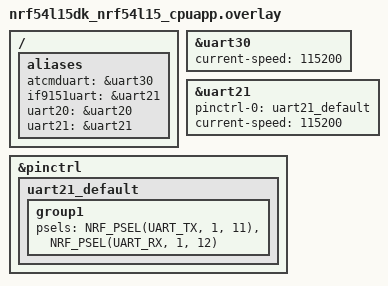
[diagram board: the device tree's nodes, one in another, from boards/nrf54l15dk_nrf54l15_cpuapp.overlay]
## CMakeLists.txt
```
cmake_minimum_required(VERSION 3.20.0)
find_package(Zephyr REQUIRED HINTS $ENV{ZEPHYR_BASE})
project(nus_at_cmd)

# 納入 src 和 drivers 目錄
add_subdirectory(drivers)

target_sources(app PRIVATE
        src/main.c
        src/at_command.c
        src/hmi_uart.c
        src/cat.c
        src/value_reporter.c
        src/sensor_handler.c
)
target_link_libraries(app PRIVATE drivers__sensor__atmel__m90e26)
```

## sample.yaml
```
sample:
  name: Bluetooth Peripheral NUS
  description: Demonstrates the NUS GATT Service (Nordic UART Service)
tests:
  sample.bluetooth.peripheral_nus:
    harness: bluetooth
    platform_allow:
      - qemu_cortex_m3
      - qemu_x86
      - nrf52840dk/nrf52840
      - nrf54l15dk/nrf54l15
    integration_platforms:
      - qemu_cortex_m3
    tags: bluetooth
```

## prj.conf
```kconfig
CONFIG_BT=y
CONFIG_BT_PERIPHERAL=y
CONFIG_BT_ZEPHYR_NUS=y

CONFIG_UART_CONSOLE=y
CONFIG_NEWLIB_LIBC=y
CONFIG_NEWLIB_LIBC_FLOAT_PRINTF=y
CONFIG_RING_BUFFER=y
CONFIG_LOG=y

# 啟用 UART 驅動
CONFIG_UART_ASYNC_API=y
# CONFIG_UART_INTERRUPT_DRIVEN=y
CONFIG_UART_USE_RUNTIME_CONFIGURE=y
# 啟用日誌
CONFIG_LOG=y
CONFIG_LOG_DEFAULT_LEVEL=3
CONFIG_LOG_MODE_DEFERRED=y

CONFIG_MAIN_STACK_SIZE=2048

CONFIG_RTIO=y
#CONFIG_M90E26_UART_DRIVER=y
```

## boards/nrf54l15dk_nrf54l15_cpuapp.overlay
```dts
/ {
    aliases {
        atcmduart = &uart30;
        if9151uart= &uart21;
        uart20 = &uart20;
        uart21 = &uart21;
    };
};

&uart30 {
    status = "okay";
    current-speed = <115200>;
};

&uart21 {
    status = "okay";
    pinctrl-0 = <&uart21_default>;
    pinctrl-names = "default";
    current-speed = <115200>;
};

&pinctrl {
    uart21_default: uart21_default {
        group1 {
            psels = <NRF_PSEL(UART_TX, 1, 11)>, <NRF_PSEL(UART_RX, 1, 12)>;
        };
    };
};
```

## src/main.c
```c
/*
 * Copyright (c) 2024 Croxel, Inc.
 *
 * SPDX-License-Identifier: Apache-2.0
 */

#include <zephyr/kernel.h>
#include <zephyr/bluetooth/bluetooth.h>
#include <zephyr/bluetooth/services/nus.h>
#include <zephyr/sys/ring_buffer.h>
#include "value_reporter.h"
#include "sensor_handler.h"

#define DEVICE_NAME		CONFIG_BT_DEVICE_NAME
#define DEVICE_NAME_LEN		(sizeof(DEVICE_NAME) - 1)

extern struct ring_buf uart_at_ringbuf;
static const struct bt_data ad[] = {
	BT_DATA_BYTES(BT_DATA_FLAGS, (BT_LE_AD_GENERAL | BT_LE_AD_NO_BREDR)),
	BT_DATA(BT_DATA_NAME_COMPLETE, DEVICE_NAME, DEVICE_NAME_LEN),
};

static const struct bt_data sd[] = {
	BT_DATA_BYTES(BT_DATA_UUID128_ALL, BT_UUID_NUS_SRV_VAL),
};

static void notif_enabled(bool enabled, void *ctx)
{
	ARG_UNUSED(ctx);

	printk("%s() - %s\n", __func__, (enabled ? "Enabled" : "Disabled"));
}

static void received(struct bt_conn *conn, const void *data, uint16_t len, void *ctx)
{
	char message[CONFIG_BT_L2CAP_TX_MTU + 1] = "";

	ARG_UNUSED(conn);
	ARG_UNUSED(ctx);

	memcpy(message, data, MIN(sizeof(message) - 1, len));
	if (ring_buf_put(&uart_at_ringbuf
                , data
                , len) == 0) {
                printk("BT: Failed to put message in RX queue (full?).");
            }
	printk("%s() - Len: %d, Message: %s\n", __func__, len, message);
}

struct bt_nus_cb nus_listener = {
	.notif_enabled = notif_enabled,
	.received = received,
};

int main(void)
{
	int err;

	printk("Sample - Bluetooth Peripheral NUS\n");

	err = bt_nus_cb_register(&nus_listener, NULL);
	if (err) {
		printk("Failed to register NUS callback: %d\n", err);
		return err;
	}

	err = bt_enable(NULL);
	if (err) {
		printk("Failed to enable bluetooth: %d\n", err);
		return err;
	}

	err = bt_le_adv_start(BT_LE_ADV_CONN_FAST_1, ad, ARRAY_SIZE(ad), sd, ARRAY_SIZE(sd));
	if (err) {
		printk("Failed to start advertising: %d\n", err);
		return err;
	}
	sensor_handler_init();
	value_reporter_start();
	printk("Initialization complete\n");

	while (true) {
		k_sleep(K_SECONDS(1));
	}

	return 0;
}
```

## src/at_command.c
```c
#include <zephyr/kernel.h>
#include <zephyr/drivers/uart.h>
#include <zephyr/logging/log.h>
#include <string.h>
#include <stdio.h>
#include <zephyr/sys/ring_buffer.h>
#include "hmi_uart.h"
#include "cat.h"
#include "value_reporter.h"

LOG_MODULE_REGISTER(at_parser_app, LOG_LEVEL_INF);

// --- Zephyr 相關定義 ---
#define STACK_SIZE 8192
#define THREAD_PRIORITY 7
#define AT_CMD_UART DT_ALIAS(atcmduart)
RING_BUF_DECLARE(uart_at_ringbuf, 1024);
struct hmi_uart_data at_cmd_uart_instance_data = {.dev = DEVICE_DT_GET(AT_CMD_UART), .rx_rbuf = &uart_at_ringbuf};
K_MUTEX_DEFINE(cat_mutex);

// --- 全局變數定義 ---
static char g_manufacture_id[32] = "MyCompany";
static char g_model_id[32] = "AT_Parser_Demo";
static char g_revision[32] = "v1.0.0";
static char g_serial_number[32] = "1234567890";
static char g_hardware_revision[32] = "HW_A1";
static uint8_t g_sysreg_rw = 0;
static uint32_t g_sysreg_reg = 0;
static uint32_t g_sysreg_sensor_id = 0;
static uint32_t g_sysreg_value = 0;
static uint32_t g_sysreg_interval = 0;
static char g_mqtt_client_id[64] = "cat_parser_client";
static uint16_t g_mqtt_keep_alive = 60;
static uint8_t g_mqtt_clean_session = 0;

static char g_working_buffer[256];
static bool g_quit_flag = false;

// --- 命令處理函式宣告 ---
static cat_return_state cmd_help_run(const struct cat_command *cmd);
static cat_return_state cmd_cgmi_run(const struct cat_command *cmd);
static cat_return_state cmd_cgmi_test(const struct cat_command *cmd, uint8_t *data, size_t *data_size, const size_t max_data_size);
static cat_return_state cmd_cgmm_run(const struct cat_command *cmd);
static cat_return_state cmd_cgmm_test(const struct cat_command *cmd, uint8_t *data, size_t *data_size, const size_t max_data_size);
static cat_return_state cmd_cgmr_run(const struct cat_command *cmd);
static cat_return_state cmd_cgmr_test(const struct cat_command *cmd, uint8_t *data, size_t *data_size, const size_t max_data_size);
static cat_return_state cmd_cgsn_run(const struct cat_command *cmd);
static cat_return_state cmd_cgsn_test(const struct cat_command *cmd, uint8_t *data, size_t *data_size, const size_t max_data_size);
static cat_return_state cmd_cgmh_run(const struct cat_command *cmd);
static cat_return_state cmd_cgmh_test(const struct cat_command *cmd, uint8_t *data, size_t *data_size, const size_t max_data_size);
static cat_return_state cmd_sysreg_write(const struct cat_command *cmd, const uint8_t *data, const size_t data_size, const size_t args_num);
static cat_return_state cmd_sysreg_test(const struct cat_command *cmd, uint8_t *data, size_t *data_size, const size_t max_data_size);
static cat_return_state cmd_xmqttcfg_read(const struct cat_command *cmd, uint8_t *data, size_t *data_size, const size_t max_data_size);
static cat_return_state cmd_xmqttcfg_write(const struct cat_command *cmd, const uint8_t *data, const size_t data_size, const size_t args_num);
static cat_return_state cmd_xmqttcfg_test(const struct cat_command *cmd, uint8_t *data, size_t *data_size, const size_t max_data_size);

// --- 命令變數描述符定義 ---
static struct cat_variable g_sysreg_vars[] = {
    { .name = "r/w", .type = CAT_VAR_UINT_DEC, .data = &g_sysreg_rw, .data_size = sizeof(g_sysreg_rw), .access = CAT_VAR_ACCESS_READ_WRITE },
    { .name = "sensor_id", .type = CAT_VAR_UINT_DEC, .data = &g_sysreg_sensor_id, .data_size = sizeof(g_sysreg_sensor_id), .access = CAT_VAR_ACCESS_READ_WRITE },
    { .name = "reg", .type = CAT_VAR_BUF_HEX, .data = &g_sysreg_reg, .data_size = sizeof(g_sysreg_reg), .access = CAT_VAR_ACCESS_READ_WRITE },
    { .name = "value", .type = CAT_VAR_UINT_DEC, .data = &g_sysreg_value, .data_size = sizeof(g_sysreg_value), .access = CAT_VAR_ACCESS_READ_WRITE },
    { .name = "interval", .type = CAT_VAR_UINT_DEC, .data = &g_sysreg_interval, .data_size = sizeof(g_sysreg_interval), .access = CAT_VAR_ACCESS_READ_WRITE },
};

static struct cat_variable g_mqtt_vars[] = {
    { .name = "client_id", .type = CAT_VAR_BUF_STRING, .data = &g_mqtt_client_id, .data_size = sizeof(g_mqtt_client_id), .access = CAT_VAR_ACCESS_READ_WRITE },
    { .name = "keep_alive", .type = CAT_VAR_UINT_DEC, .data = &g_mqtt_keep_alive, .data_size = sizeof(g_mqtt_keep_alive), .access = CAT_VAR_ACCESS_READ_WRITE },
    { .name = "clean_session", .type = CAT_VAR_UINT_DEC, .data = &g_mqtt_clean_session, .data_size = sizeof(g_mqtt_clean_session), .access = CAT_VAR_ACCESS_READ_WRITE },
};

// --- 命令描述符定義 ---
static struct cat_command g_cmds[] = {
    { .name = "+CGMI", .description = "Requests manufacture identification.", .run = cmd_cgmi_run, .test = cmd_cgmi_test },
    { .name = "+CGMM", .description = "Requests model identification.", .run = cmd_cgmm_run, .test = cmd_cgmm_test },
    { .name = "+CGMR", .description = "Requests revision identification.", .run = cmd_cgmr_run, .test = cmd_cgmr_test },
    { .name = "+CGSN", .description = "Requests product serial number identification.", .run = cmd_cgsn_run, .test = cmd_cgsn_test },
    { .name = "+CGMH", .description = "Requests hardware revision.", .run = cmd_cgmh_run, .test = cmd_cgmh_test },
    {
        .name = "+SYSREG",
        .description = "System register R/W operation.",
        .write = cmd_sysreg_write,
        .test = cmd_sysreg_test,
        .var = g_sysreg_vars,
        .var_num = sizeof(g_sysreg_vars) / sizeof(g_sysreg_vars[0]),
    },
    {
        .name = "#XMQTTCFG",
        .description = "MQTT client configuration.",
        .write = cmd_xmqttcfg_write,
        .read = cmd_xmqttcfg_read,
        .test = cmd_xmqttcfg_test,
        .var = g_mqtt_vars,
        .var_num = sizeof(g_mqtt_vars) / sizeof(g_mqtt_vars[0]),
    },
    { .name = "#HELP", .description = "Prints a list of all available commands.", .run = cmd_help_run },
};

// --- Zephyr I/O 介面實現 ---
static int write_char(char ch) {
    LOG_DBG("Sent: %c\n",(ch));
    hmi_uart_send(at_cmd_uart_instance_data.dev, &ch, 1);
    return 1;
}

static int read_char(char *ch) {
    int ret = 0;
    ret = ring_buf_get(&uart_at_ringbuf, ch, 1);
    if(ret != 0)
    {
        LOG_DBG("Get: %c\n",(uint8_t)(*ch));
        //LOG_INF("head:%d,tail:%d,base:%d\n",uart_at_ringbuf.get_head,uart_at_ringbuf.get_tail,uart_at_ringbuf.get_base);
        
        return 1;
    }
    return 0;
}

// --- 互斥鎖介面實現 ---
static int mutex_lock(void) {
    return k_mutex_lock(&cat_mutex, K_FOREVER);
}

static int mutex_unlock(void) {
    return k_mutex_unlock(&cat_mutex);
}

static struct cat_io_interface g_iface = {
    .read = read_char,
    .write = write_char
};

static struct cat_mutex_interface g_mutex = {
    .lock = mutex_lock,
    .unlock = mutex_unlock
};

static cat_return_state cmd_help_run(const struct cat_command *cmd) {
    LOG_INF("Execute Help");
    return CAT_RETURN_STATE_PRINT_CMD_LIST_OK;
}

static cat_return_state cmd_cgmi_run(const struct cat_command *cmd) {
    printk("%s\n", g_manufacture_id);
    return CAT_RETURN_STATE_OK;
}
static cat_return_state cmd_cgmi_test(const struct cat_command *cmd, uint8_t *data, size_t *data_size, const size_t max_data_size) {
    return CAT_RETURN_STATE_OK;
}

static cat_return_state cmd_cgmm_run(const struct cat_command *cmd) {
    printk("%s\n", g_model_id);
    return CAT_RETURN_STATE_OK;
}
static cat_return_state cmd_cgmm_test(const struct cat_command *cmd, uint8_t *data, size_t *data_size, const size_t max_data_size) {
    return CAT_RETURN_STATE_OK;
}

static cat_return_state cmd_cgmr_run(const struct cat_command *cmd) {
    printk("%s\n", g_revision);
    return CAT_RETURN_STATE_OK;
}
static cat_return_state cmd_cgmr_test(const struct cat_command *cmd, uint8_t *data, size_t *data_size, const size_t max_data_size) {
    return CAT_RETURN_STATE_OK;
}

static cat_return_state cmd_cgsn_run(const struct cat_command *cmd) {
    printk("%s\n", g_serial_number);
    return CAT_RETURN_STATE_OK;
}
static cat_return_state cmd_cgsn_test(const struct cat_command *cmd, uint8_t *data, size_t *data_size, const size_t max_data_size) {
    return CAT_RETURN_STATE_OK;
}

static cat_return_state cmd_cgmh_run(const struct cat_command *cmd) {
    printk("%s\n", g_hardware_revision);
    return CAT_RETURN_STATE_OK;
}
static cat_return_state cmd_cgmh_test(const struct cat_command *cmd, uint8_t *data, size_t *data_size, const size_t max_data_size) {
    return CAT_RETURN_STATE_OK;
}

static cat_return_state cmd_sysreg_write(const struct cat_command *cmd, const uint8_t *data, const size_t data_size, const size_t args_num) {
    uint32_t result = 0;

    LOG_INF("+SYSREG:%d, %u, %02X,%u,%u\n", g_sysreg_rw, g_sysreg_sensor_id, g_sysreg_reg, g_sysreg_value, g_sysreg_interval);
    result = value_reporter_set_report_period(g_sysreg_sensor_id, g_sysreg_reg, g_sysreg_interval);
    if(result != g_sysreg_interval)
    {
        return CAT_RETURN_STATE_ERROR;
    }

    return CAT_RETURN_STATE_OK;
}
static cat_return_state cmd_sysreg_test(const struct cat_command *cmd, uint8_t *data, size_t *data_size, const size_t max_data_size) {
    return CAT_RETURN_STATE_OK;
}

static cat_return_state cmd_xmqttcfg_read(const struct cat_command *cmd, uint8_t *data, size_t *data_size, const size_t max_data_size) {
    int written = snprintf((char*)data, max_data_size, "+XMQTTCFG:\"%s\",%u,%u", g_mqtt_client_id, g_mqtt_keep_alive, g_mqtt_clean_session);
    if (written > 0) {
        *data_size = written;
    }
    return CAT_RETURN_STATE_DATA_OK;
}
static cat_return_state cmd_xmqttcfg_write(const struct cat_command *cmd, const uint8_t *data, const size_t data_size, const size_t args_num) {
    LOG_INF("MQTT config updated: client_id=\"%s\", keep_alive=%u, clean_session=%u", g_mqtt_client_id, g_mqtt_keep_alive, g_mqtt_clean_session);
    return CAT_RETURN_STATE_OK;
}
static cat_return_state cmd_xmqttcfg_test(const struct cat_command *cmd, uint8_t *data, size_t *data_size, const size_t max_data_size) {
    return CAT_RETURN_STATE_OK;
}

// --- AT 解析器執行緒 ---
static void at_parser_thread(void *p1, void *p2, void *p3) {
    struct cat_object at;
    
    struct cat_command_group g_cmd_group_obj = {
        .cmd = g_cmds,
        .cmd_num = sizeof(g_cmds) / sizeof(g_cmds[0]),
    };
    
    struct cat_command_group *g_cmd_desc[] = {
        &g_cmd_group_obj
    };

    struct cat_descriptor g_desc = {
        .cmd_group = g_cmd_desc,
        .cmd_group_num = sizeof(g_cmd_desc) / sizeof(g_cmd_desc[0]),
        .buf = (uint8_t *)g_working_buffer,
        .buf_size = sizeof(g_working_buffer),
    };

    if (hmi_uart_init_instance(&at_cmd_uart_instance_data, 115200)) {
        LOG_ERR("AT CMD UART device not ready!");
        return;
    }
    
    cat_init(&at, &g_desc, &g_iface, &g_mutex);
    LOG_INF("AT Command Parser Thread Started");
    
    // Initial banner
    LOG_INF("AT Command Parser Demo\n");
    LOG_INF("Type AT#HELP to see the command list.\n");

    while (!g_quit_flag) {
        cat_service(&at);
        k_msleep(1);
    }
}

K_THREAD_DEFINE(at_parser_tid, STACK_SIZE, at_parser_thread, NULL, NULL, NULL, THREAD_PRIORITY, 0, 0);
```

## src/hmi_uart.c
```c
#include "hmi_uart.h"
#include <string.h>
#include <zephyr/sys/ring_buffer.h>

// 註冊日誌模組
LOG_MODULE_REGISTER(hmi_uart_module, LOG_LEVEL_INF);

// 靜態函數聲明
static void hmi_uart_callback_internal(const struct device *dev, struct uart_event *evt, void *user_data);

// 內部 UART 回調函數
// 這個回調函數將處理所有由 Zephyr UART 驅動發出的事件，並將其分發到正確的 hmi_uart_data 實例。
static void hmi_uart_callback_internal(const struct device *dev, struct uart_event *evt, void *user_data)
{
    struct hmi_uart_data *data = (struct hmi_uart_data *)user_data;

    if (data == NULL) {
        LOG_ERR("UART callback received NULL user_data for %s!", dev->name);
        return;
    }

    switch (evt->type) {
        case UART_RX_RDY: {
            LOG_HEXDUMP_DBG(&evt->data.rx.buf[evt->data.rx.offset], evt->data.rx.len, "Put:");
            if (ring_buf_put(data->rx_rbuf
                , &evt->data.rx.buf[evt->data.rx.offset]
                , evt->data.rx.len) == 0) {
                LOG_WRN("%s: 1 Failed to put message in RX queue (full?).", data->dev->name);
            }
            break;
        }
        case UART_RX_STOPPED: {
            //LOG_INF("%s: UART_RX_STOPPED", dev->name);
            break;
        }
        case UART_RX_BUF_REQUEST:
        {
            if(data->rx_buf_idx == 0)
            {
                data->rx_buf_idx = 1;
            }else
            {
                data->rx_buf_idx = 0;
            }
            uart_rx_buf_rsp(dev, data->rx_buf[data->rx_buf_idx], HMI_UART_RX_MSG_SIZE);
            break;
        }
        case UART_RX_BUF_RELEASED:
            // 緩衝區釋放事件，用於資源管理
            break;
        case UART_RX_DISABLED:
        {
            int ret = 0;
            if(data->rx_buf_idx == 0)
            {
                data->rx_buf_idx = 1;
            }else
            {
                data->rx_buf_idx = 0;
            }
            ret = uart_rx_enable(dev, data->rx_buf[data->rx_buf_idx], HMI_UART_RX_MSG_SIZE, 100);
            if (ret) {
                LOG_ERR("啟用 UART %s 接收失敗: %d", dev->name, ret);
            }
            //LOG_INF("%s: UART_RX_DISABLED", dev->name);
            break;
        }
        case UART_TX_DONE:
            // 傳輸完成事件。如果需要，可以在此處理 TX 完成的邏輯
            // 例如，釋放 TX 緩衝區或通知等待的線程
            LOG_DBG("%s: UART_TX_DONE", dev->name);
            break;

        case UART_TX_ABORTED:
            //LOG_WRN("%s: UART_EVT_TX_ABORTED", dev->name);
            break;

        default:
            // 處理其他未知的 UART 事件
            break;
    }
}

int hmi_uart_init_instance(struct hmi_uart_data *instance_data, uint32_t baud_rate)
{
    const struct device *uart_dev = instance_data->dev;
    struct uart_config uart_cfg = {
        .baudrate = baud_rate,
        .parity = UART_CFG_PARITY_NONE,
        .stop_bits = UART_CFG_STOP_BITS_1,
        .data_bits = UART_CFG_DATA_BITS_8,
        .flow_ctrl = UART_CFG_FLOW_CTRL_NONE
    };
    int ret;

    if (!device_is_ready(uart_dev)) {
        LOG_ERR("UART 設備 %s 未準備就緒！", uart_dev->name);
        return -ENODEV;
    }

    if (instance_data == NULL) {
        LOG_ERR("hmi_uart_init_instance 接收到 NULL 指針！");
        return -EINVAL;
    }

    // 將外部提供的數據結構和消息佇列指針賦值給實例
    instance_data->dev = uart_dev;
    instance_data->rx_buf_pos = 0;

    ret = uart_configure(uart_dev, &uart_cfg);
    if (ret) {
        LOG_ERR("配置 UART 設備 %s 失敗: %d", uart_dev->name, ret);
        return ret;
    }

    // 設置回調函數，將實例數據指針作為 user_data 傳遞
    ret = uart_callback_set(uart_dev, hmi_uart_callback_internal, (void *)instance_data);
    if (ret) {
        LOG_ERR("設定 UART %s 回調失敗: %d", uart_dev->name, ret);
        return ret;
    }

    // 啟用接收，使用實例的接收緩衝區
    ret = uart_rx_enable(uart_dev, instance_data->rx_buf[0], HMI_UART_RX_MSG_SIZE, 100);
    if (ret) {
        LOG_ERR("啟用 UART %s 接收失敗: %d", uart_dev->name, ret);
        return ret;
    }

    LOG_INF("HMI UART 模組 %s 初始化成功，波特率: %d", uart_dev->name, baud_rate);
    return 0;
}

int hmi_uart_send(const struct device *uart_dev, const uint8_t *data, size_t len)
{
    if (!device_is_ready(uart_dev)) {
        LOG_ERR("UART 設備 %s 未準備就緒，無法傳送！", uart_dev->name);
        return -ENODEV;
    }

    int ret = uart_tx(uart_dev, data, len, SYS_FOREVER_US);
    if (ret < 0) {
        LOG_ERR("UART %s 寫入 FIFO 失敗: %d", uart_dev->name, ret);
    }
    return ret; // 返回
}
```

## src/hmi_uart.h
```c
#ifndef HMI_UART_H__
#define HMI_UART_H__

#include <zephyr/kernel.h>
#include <zephyr/drivers/uart.h>
#include <zephyr/logging/log.h>

// UART 接收緩衝區大小
#define HMI_UART_RX_MSG_SIZE (64) //
#define HMI_UART_RX_BUFF_NEM (2)
/**
 * @brief HMI UART 實例的數據結構。
 * 包含每個 UART 實例的運行時數據。
 */
struct hmi_uart_data {
    const struct device *dev;         // UART 設備指針
    uint8_t rx_buf[HMI_UART_RX_BUFF_NEM][HMI_UART_RX_MSG_SIZE]; // 接收緩衝區
    uint8_t rx_buf_idx;
    size_t rx_buf_pos;                // 接收緩衝區當前位置
    struct ring_buf *rx_rbuf;           // 綁定到此實例的接收消息隊列指針
};

/**
 * @brief 初始化 HMI UART 模組的特定實例。
 *
 * @param instance_data 指向 HMI UART 數據結構的指針，用於儲存實例的運行時數據。
 * @param baud_rate 要設置的 UART 波特率。
 * 此數據結構和其內部消息佇列應由外部調用者定義和管理。
 *
 * @return 回傳傳送成功或失敗，0為成功，負數 errno 表示失敗。
 */
int hmi_uart_init_instance(struct hmi_uart_data *instance_data, uint32_t baud_rate);

/**
 * @brief 向指定的 HMI UART 設備發送數據 (非阻塞)。
 *
 * @param uart_dev 指向要發送數據的 UART 設備的指針。
 * @param data 指向要發送數據的緩衝區的指針。
 * @param len 要發送的數據長度。
 *
 * @return 回傳傳送成功或失敗，0為成功，負數 errno 表示失敗。
 */
int hmi_uart_send(const struct device *uart_dev, const uint8_t *data, size_t len);

#endif // HMI_UART_H__
```

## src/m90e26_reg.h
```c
#ifndef M90E26_REG_H_
#define M90E26_REG_H_

#define TOTAL_REG_NUM   21
enum ATM90E26_ENG_REGSTERS {
    APENG = 0x40,
    ANENG = 0x41,
    ATENG = 0x42,
    RPENG = 0x43,
    RNENG = 0x44,
    RTENG = 0x45,
    ENSTAT = 0x46,
    IRMS = 0x48,
    URMS = 0x49,
    PMEAN = 0x4A,
    QMEAN = 0x4B,
    FREQ = 0x4C,
    POWERF = 0x4D,
    PANG = 0x4E,
    SMEAN = 0x4F,
    IRMS2 = 0x68,
    PMEAN2 = 0x6A,
    QMEAN2 = 0x6B,
    POWERF2 = 0x6D,
    PANG2 = 0x6E,
    SMEAN2 = 0x6F
};

#endif /* M90E26_REG_H_ */
```

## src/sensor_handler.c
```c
#include <zephyr/kernel.h>
#include <zephyr/device.h>
#include <zephyr/rtio/rtio.h>
#include <zephyr/sys/byteorder.h>
#include <zephyr/sys/atomic.h>
#include <zephyr/init.h>
#include <zephyr/logging/log.h>

#include "sensor_handler.h"
#include "m90e26_reg.h"

LOG_MODULE_REGISTER(sensor_handler, LOG_LEVEL_INF);

// --- 內部定義 ---
static const uint8_t regs_to_poll[] = {
	APENG, ANENG, ATENG, RPENG, RNENG, RTENG, ENSTAT,
	IRMS, URMS, PMEAN, QMEAN, FREQ, POWERF, PANG, SMEAN,
	IRMS2, PMEAN2, QMEAN2, POWERF2, PANG2, SMEAN2
};

#define NUM_REGS_TO_POLL (sizeof(regs_to_poll) / sizeof(regs_to_poll[0]))
#define TOTAL_REQUESTS (SENSOR_HANDLER_NUM_INSTANCES * NUM_REGS_TO_POLL)

struct m90e26_instance {
	const struct device *dev;
	const struct rtio_iodev *iodev; // <<< 新增：儲存 iodev 指標
	char *name;
	struct k_mutex lock;
	// 資料快取區
	uint16_t apeng, aneng, ateng, rpeng, rneng, rteng, enstat;
	uint16_t irms, urms, pmean, qmean, freq, powerf, pang, smean;
	uint16_t irms2, pmean2, qmean2, powerf2, pang2, smean2;
};

struct cqe_user_context {
	struct m90e26_instance *instance;
	uint8_t reg_addr;
	uint16_t result_buf; // <<< 修改：讓每個上下文自帶一個緩衝區
};

// --- 模組內部靜態變數 ---
static struct m90e26_instance instances[SENSOR_HANDLER_NUM_INSTANCES];
static struct cqe_user_context context_pool[TOTAL_REQUESTS];
RTIO_DEFINE(m90e26_rtio_ctx, TOTAL_REQUESTS, TOTAL_REQUESTS);
atomic_t pending_responses;
static struct k_timer periodic_read_timer;

// --- 背景更新邏輯 ---
static void completion_cb(const struct rtio *r, struct rtio_cqe *cqe)
{
	struct cqe_user_context *ctx = cqe->userdata;
	uint16_t received_val = ctx->result_buf; // <<< 修改：從上下文的緩衝區讀取

	if (cqe->result == 0) {
		switch (ctx->reg_addr) {
		case APENG:  ctx->instance->apeng = received_val; break;
		/* ... (其他 case 與先前相同) ... */
		case URMS:   ctx->instance->urms = received_val; break;
		case IRMS:   ctx->instance->irms = received_val; break;
		case PMEAN:  ctx->instance->pmean = received_val; break;
		case SMEAN2:  ctx->instance->smean2 = received_val; break;
		}
	} else {
		LOG_ERR("Failed to read reg 0x%02x from %s (err: %d)",
			ctx->reg_addr, ctx->instance->name, cqe->result);
	}

	if (atomic_dec(&pending_responses) == 1) {
		LOG_INF("--- Background poll cycle finished ---");
		for (int i = 0; i < SENSOR_HANDLER_NUM_INSTANCES; i++) {
			k_mutex_unlock(&instances[i].lock);
		}
	}
}

static void periodic_read_timer_handler(struct k_timer *timer)
{
	LOG_INF("--- Background poll cycle starting ---");
	for (int i = 0; i < SENSOR_HANDLER_NUM_INSTANCES; i++) {
		if (k_mutex_lock(&instances[i].lock, K_MSEC(50)) != 0) {
			LOG_WRN("Could not lock instance %s, skipping poll.", instances[i].name);
			return;
		}
	}
	atomic_set(&pending_responses, TOTAL_REQUESTS);
	int ctx_idx = 0;
	for (int i = 0; i < SENSOR_HANDLER_NUM_INSTANCES; i++) {
		for (int j = 0; j < NUM_REGS_TO_POLL; j++) {
			struct m90e26_instance *inst = &instances[i];
			uint8_t reg = regs_to_poll[j];

			// <<< 修改：API 更新 >>>
			struct rtio_sqe *sqe = rtio_sqe_acquire(&m90e26_rtio_ctx);
			if (!sqe) {
				LOG_ERR("Failed to acquire SQE!");
				atomic_sub(&pending_responses, TOTAL_REQUESTS - ctx_idx);
				for(int k=0; k<SENSOR_HANDLER_NUM_INSTANCES; k++) k_mutex_unlock(&instances[k].lock);
				return;
			}
			context_pool[ctx_idx] = (struct cqe_user_context){ .instance = inst, .reg_addr = reg };
			sqe->userdata = &context_pool[ctx_idx];

			// <<< 修改：API 更新 >>>
			rtio_sqe_prep_read(sqe, inst->iodev, RTIO_PRIO_NORM,
					   (uint8_t*)&context_pool[ctx_idx].result_buf, // 寫入到上下文的緩衝區
					   sizeof(uint16_t),
					   (void *)(uintptr_t)reg);
			ctx_idx++;
		}
	}
	// <<< 修改：API 更新 >>>
	rtio_submit(&m90e26_rtio_ctx, TOTAL_REQUESTS);
}

// --- 公開 API 函式實作 ---
int sensor_handler_init(void)
{
	// <<< 修改：在 init 中初始化 instances 陣列 >>>
	const struct device *devs[] = {
		DEVICE_DT_GET(DT_NODELABEL(m90e26_A)),
		DEVICE_DT_GET(DT_NODELABEL(m90e26_B)),
		DEVICE_DT_GET(DT_NODELABEL(m90e26_C)),
	};
	const char *names[] = {"M90E26_A", "M90E26_B", "M90E26_C"};

	for (int i = 0; i < SENSOR_HANDLER_NUM_INSTANCES; i++) {
		instances[i].dev = devs[i];
		instances[i].name = (char*)names[i];
		if (!device_is_ready(instances[i].dev)) {
			LOG_ERR("Device %s is not ready!", instances[i].name);
			return -ENODEV;
    }
}
```

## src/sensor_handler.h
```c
#ifndef SENSOR_HANDLER_H_
#define SENSOR_HANDLER_H_

#include <stdint.h>

/**
 * @file
 * @brief Sensor Handler 模組的公開 API。
 *
 * 此模組負責在背景中定期從多個 M90E26 感測器讀取數據，
 * 並提供一個執行緒安全 (thread-safe) 的 API 來存取最新的快取感測器數值。
 */

/**
 * @brief 由此處理程序管理的 M90E26 感測器實例數量。
 *
 * 應用層可以使用此常數來遍歷所有可用的感測器。
 */
#define SENSOR_HANDLER_NUM_INSTANCES 3

/**
 * @brief 初始化 sensor_handler 模組。
 *
 * 此函式必須在啟動時呼叫一次。它會初始化所有感測器設備實例、
 * 設定內部 RTIO 上下文，並啟動週期性的背景輪詢計時器。
 *
 * @retval 0 成功。
 * @retval -ENODEV 如果一個或多個 M90E26 感測器設備未就緒。
 */
int sensor_handler_init(void);

/**
 * @brief 從指定感測器的快取中獲取特定暫存器的值。
 *
 * 此函式擷取由背景輪詢任務取得的最新數值。它從內部快取讀取，
 * 本身不執行任何硬體 I/O 操作。此函式是非阻塞的，並且是執行緒安全的。
 *
 * @param sensorId 要查詢的感測器實例索引 (範圍從 0 到 SENSOR_HANDLER_NUM_INSTANCES - 1)。
 * @param reg 要讀取的 8 位元暫存器位址。該暫存器必須是背景任務
 * 正在輪詢的暫存器之一 (例如，來自 m90e26_reg.h 的 URMS, IRMS)。
 * @param val 一個指向 uint16_t 變數的指標，用於儲存暫存器的值。
 *
 * @retval 0 成功。
 * @retval -EINVAL 如果提供的 sensorId 超出範圍。
 * @retval -ENOTSUP 如果請求的暫存器 `reg` 不在背景輪詢列表中，因此在快取中不可用。
 */
int sensor_handler_get_m90e26_reg_value(uint8_t sensorId, uint8_t reg, uint16_t *val);

#endif /* SENSOR_HANDLER_H_ */
```

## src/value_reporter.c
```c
#include <stdio.h>
#include <stdint.h>
#include <string.h>
#include <zephyr/sys/ring_buffer.h>
#include "hmi_uart.h"
#include "value_reporter.h"
#include "sensor_handler.h"

LOG_MODULE_REGISTER(value_reporter, LOG_LEVEL_INF);
#define IF_9151_UART DT_ALIAS(if9151uart)

static uint32_t report_last_tick[TOTAL_SENSOR_ID][TOTAL_REG_NUM];
static uint32_t report_periods[TOTAL_SENSOR_ID][TOTAL_REG_NUM];
RING_BUF_DECLARE(if_9151_ringbuf, 1024);
struct hmi_uart_data if_9151_uart_instance_data = {.dev = DEVICE_DT_GET(IF_9151_UART), .rx_rbuf=&if_9151_ringbuf};


static int value_reporter_make_report(char *buff, size_t buff_size, uint8_t sensorId, uint8_t reg, uint16_t val, uint32_t period);
static int atm90e26_get_register_index(enum ATM90E26_ENG_REGSTERS reg);
static bool value_reporter_check_reg_need_report(uint8_t sensor_id, uint8_t reg, uint32_t last_tick, uint32_t current_tick);
static void value_reporter_timer_handler(void *p1, void *p2, void *p3);

static const enum ATM90E26_ENG_REGSTERS register_map[] = {
    APENG,   ANENG,   ATENG,
    RPENG,   RNENG,   RTENG,
    ENSTAT,  IRMS,    URMS,
    PMEAN,   QMEAN,   FREQ,
    POWERF,  PANG,    SMEAN,
    IRMS2,   PMEAN2,  QMEAN2,
    POWERF2, PANG2,   SMEAN2
};


static int atm90e26_get_register_index(enum ATM90E26_ENG_REGSTERS reg) {
    switch (reg) {
        case APENG:   return 0;
        case ANENG:   return 1;
        case ATENG:   return 2;
        case RPENG:   return 3;
        case RNENG:   return 4;
        case RTENG:   return 5;
        case ENSTAT:  return 6;
        case IRMS:    return 7;
        case URMS:    return 8;
        case PMEAN:   return 9;
        case QMEAN:   return 10;
        case FREQ:    return 11;
        case POWERF:  return 12;
        case PANG:    return 13;
        case SMEAN:   return 14;
        case IRMS2:   return 15;
        case PMEAN2:  return 16;
        case QMEAN2:  return 17;
        case POWERF2: return 18;
        case PANG2:   return 19;
        case SMEAN2:  return 20;
        default:      return REG_NOT_VALIDE; // 代表錯誤或未知的位址
    }
}

uint32_t value_reporter_set_report_period(uint8_t sensorId, uint8_t reg, uint32_t period)
{
    int reg_index = 0;
    reg_index = atm90e26_get_register_index(reg);
    if(sensorId >= TOTAL_SENSOR_ID || sensorId < 0)
    {
        return PERIOD_NOT_VALIDE;
    }

    if(reg_index == REG_NOT_VALIDE)
    {
        return PERIOD_NOT_VALIDE;
    }
    report_periods[sensorId][reg_index] = period;
    LOG_DBG("Set period: %u, %02X, %u, %u", sensorId, reg, reg_index, period);
    return report_periods[sensorId][reg_index];
}

static int value_reporter_make_report(char *buff, size_t buff_size, uint8_t sensorId, uint8_t reg, uint16_t val, uint32_t period)
{
    int ret = -1;
    //+SYSREG:<r/w (r:0, w:1)>,<SensorID (0~2)>,<reg (hex)>,<value (hex)>,<interval (s)>
    //+SYSREG:1,2,4E,32ED,9999\n
    if((buff == NULL) || (buff_size < MAX_REPORT_LEN))
    {
        return -1;
    }

    if(period > MAX_PERIOD || period < 0)
    {
        return -1;
    }

    ret = snprintf(buff, MAX_REPORT_LEN
        , "+SYSREG:0,%01u,%02X,%04X,%04u\r\n"
        ,sensorId, reg, val, period);
    LOG_INF("Make report: %d", ret);
    if(ret <= 0)
    {
        return -1;
    }

    return 0;
}

static bool value_reporter_check_reg_need_report(uint8_t sensor_id, uint8_t reg, uint32_t last_tick, uint32_t current_tick)
{
    uint32_t period = 0;
    int reg_idx = REG_NOT_VALIDE;

    reg_idx = atm90e26_get_register_index(reg);

    if(reg_idx == REG_NOT_VALIDE)
    {
        return false;
    }

    if(sensor_id >= TOTAL_SENSOR_ID || sensor_id < 0)
    {
        return false;
    }

    period = report_periods[sensor_id][atm90e26_get_register_index(reg)];
    if(period == 0)
    {
        return false;
    }

    if(current_tick - last_tick >= period)
    {
        return true;
    }else
    {
        return false;
    }

    return false;
}
char report_buff[MAX_REPORT_LEN] = {0};
static void value_reporter_timer_handler(void *p1, void *p2, void *p3) {

    static uint32_t current_tick = 0;
    memset(report_buff, 0, MAX_REPORT_LEN);
    for(int id = 0; id < TOTAL_SENSOR_ID; id++)
    {
        for(int reg_idx = 0; reg_idx < TOTAL_REG_NUM; reg_idx++)
        {
            bool need_report = false;
            need_report = value_reporter_check_reg_need_report(id, register_map[reg_idx], report_last_tick[id][reg_idx], current_tick);

            if(need_report)
            {
                uint16_t reg_val = sensor_handler_get_reg_value(id, reg_idx);
                uint32_t period = report_periods[id][reg_idx];
                value_reporter_make_report(report_buff, MAX_REPORT_LEN, id, register_map[reg_idx], reg_val, period);
                report_last_tick[id][reg_idx] = current_tick;
                LOG_INF("Report: %s, %u", report_buff, strlen(report_buff));
                hmi_uart_send(if_9151_uart_instance_data.dev, report_buff, strlen(report_buff));
            }
        }
    }
    current_tick++;
}
K_TIMER_DEFINE(value_reporter_timer, value_reporter_timer_handler, NULL);

bool value_reporter_start(void)
{
    if (hmi_uart_init_instance(&if_9151_uart_instance_data, 115200)) {
        LOG_ERR("9151 UART device not ready!");
        return;
    }
    k_timer_start(&value_reporter_timer, K_SECONDS(1), K_SECONDS(1));
}
```

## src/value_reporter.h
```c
#ifndef VALUE_REPORTER_H__
#define VALUE_REPORTER_H__
#include <stdint.h>
#include <zephyr/logging/log.h>
#include <zephyr/kernel.h>

#define TOTAL_SENSOR_ID 3
#define TOTAL_REG_NUM   21
#define REG_NOT_VALIDE  (-1)
#define PERIOD_DISABLE_REPORT (0x00000000)
#define PERIOD_NOT_VALIDE (0xFFFFFFFF)
#define MAX_REPORT_LEN  (27U)
#define MAX_PERIOD  (9999)
enum ATM90E26_ENG_REGSTERS {
    APENG = 0x40,
    ANENG = 0x41,
    ATENG = 0x42,
    RPENG = 0x43,
    RNENG = 0x44,
    RTENG = 0x45,
    ENSTAT = 0x46,
    IRMS = 0x48,
    URMS = 0x49,
    PMEAN = 0x4A,
    QMEAN = 0x4B,
    FREQ = 0x4C,
    POWERF = 0x4D,
    PANG = 0x4E,
    SMEAN = 0x4F,
    IRMS2 = 0x68,
    PMEAN2 = 0x6A,
    QMEAN2 = 0x6B,
    POWERF2 = 0x6D,
    PANG2 = 0x6E,
    SMEAN2 = 0x6F
};

uint32_t value_reporter_set_report_period(uint8_t sensorId, uint8_t reg, uint32_t period);
bool value_reporter_start(void);
#endif // VALUE_REPORTER_H__
```
